# DECODER0_MSVDX_VEC register map
Vendor: Texas Instruments
Peripheral module from a debugger description file (folder J7ES).
Registers are 32-bit, read-write, reset 0x0 unless marked. A register's access mark holds for its fields unless they carry their own. Offsets are as the file gives them; lines under a group give offsets from that group; [hi:lo] are bit positions; {n}, {i} and the like mark numbered series; 'fields as' and 'values as' point back to an identical list; <NAME> marks a mode.

## DECODER0_MSVDX_VEC
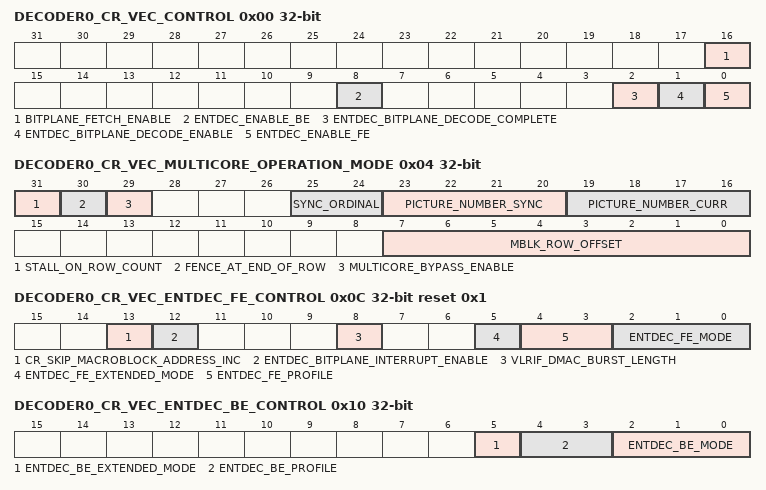
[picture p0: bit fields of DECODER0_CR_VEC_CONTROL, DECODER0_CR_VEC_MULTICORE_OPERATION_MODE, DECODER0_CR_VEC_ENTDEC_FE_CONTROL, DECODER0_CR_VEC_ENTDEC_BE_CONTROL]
0x00 DECODER0_CR_VEC_CONTROL
  [16] BITPLANE_FETCH_ENABLE — Setting this bit will cause the h/w to fetch the bit plane data from the address specified at VEC_VC1_FE_BITPLANES_BASE_ADDR0 [0x418].
  [8] ENTDEC_ENABLE_BE — Setting this bit to '1' instructs the back-end EntDec parser to start parsing the Rendec stream.
  [2] ENTDEC_BITPLANE_DECODE_COMPLETE — This is a status bit to indicate if parsing of the Bit Plane data has completed or not.
  [1] ENTDEC_BITPLANE_DECODE_ENABLE — Setting this bit to '1' instructs the VC-1 Bit Plane decoder to start parsing the stream.
  [0] ENTDEC_ENABLE_FE — Setting this bit to '1' instructs the front-end EntDec parser to start parsing the bit stream.
0x04 DECODER0_CR_VEC_MULTICORE_OPERATION_MODE
  [31] STALL_ON_ROW_COUNT — Enable the multicore support
  [30] FENCE_AT_END_OF_ROW — Insert a fence operation into the memory interface for the last write of the macroblock row before updating the macroblock row count
  [29] MULTICORE_BYPASS_ENABLE — Instead of providing the vdeb macroblock_row_count from the current core, bypass the vdeb macroblock_row_count from the upper core to the lower core in the chain
  [25:24] SYNC_ORDINAL — Sync core ordinal allows the dependent upstream core [and associated sync value] to be selected.
  [23:20] PICTURE_NUMBER_SYNC — Picture number value to be compared to the sync value passed from the upstream decode core.
  [19:16] PICTURE_NUMBER_CURR — Picture number value of the current decode to be passed to the downstream decode core.
  [7:0] MBLK_ROW_OFFSET — Macroblock row offset to be subtracted from the external macroblock row count.
0x08 DECODER0_CR_VEC_COPRO_TARGET — Controls the target module that is accessed by the MTX co-pro port.
  [2:0] COPRO_TARGET
0x0C DECODER0_CR_VEC_ENTDEC_FE_CONTROL reset 0x1
  [13] CR_SKIP_MACROBLOCK_ADDRESS_INC — Indicates that the SW has already extracted the macroblock_inc value and placed it in cr_macroblock_address_inc.
  [12] ENTDEC_BITPLANE_INTERRUPT_ENABLE — When this bit is set to '1', the completion of VC-1 Bit Plane decoding is notified via VEC_END_OF_SLICE bit of interrupt status register of MSVDX.
  [8] VLRIF_DMAC_BURST_LENGTH — DMAC-CH1 burst length control set up by VLRIF when fetching the bitplane data or slice group map data from memory.
  [5] ENTDEC_FE_EXTENDED_MODE — Provides an extension to the ENTDEC_FE_MODE field to allow additional codecs.
  [4:3] ENTDEC_FE_PROFILE — Defines profile for the front-end of Entdec [definition based on ENTDEC_FE_MODE]
  [2:0] ENTDEC_FE_MODE — Define which standard the stream [being processed by the front-end] belongs to
0x10 DECODER0_CR_VEC_ENTDEC_BE_CONTROL
  [5] ENTDEC_BE_EXTENDED_MODE — Provies an extension to the ENTDEC_BE_MODE field
  [4:3] ENTDEC_BE_PROFILE — Defines profile for the back-end of Entdec [definition based on ENTDEC_BE_MODE]
  [2:0] ENTDEC_BE_MODE — Define which standard the stream [being processed by the back-end] belongs to
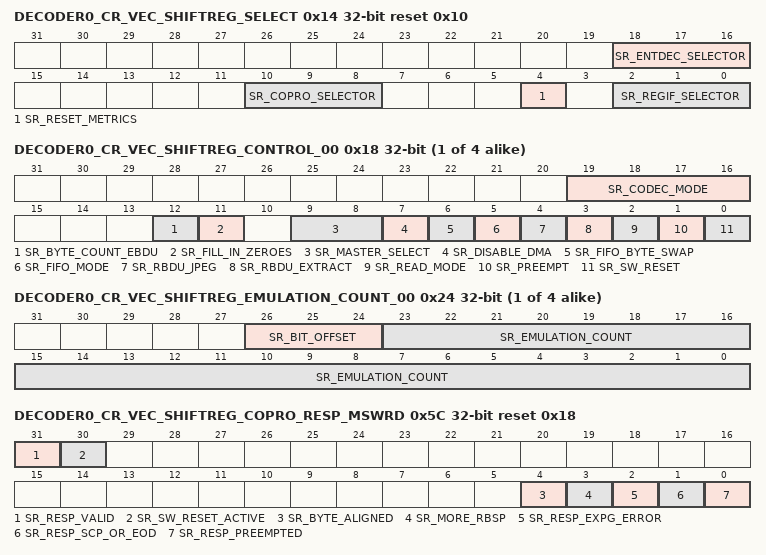
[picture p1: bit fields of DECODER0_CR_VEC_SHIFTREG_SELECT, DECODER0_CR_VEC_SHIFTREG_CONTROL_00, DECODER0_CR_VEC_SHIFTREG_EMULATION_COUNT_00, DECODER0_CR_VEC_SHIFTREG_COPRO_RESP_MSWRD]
0x14 DECODER0_CR_VEC_SHIFTREG_SELECT reset 0x10
  [18:16] SR_ENTDEC_SELECTOR — Used to select the instance of the Shift Register that can be accessed by the Entropy Decoder
  [10:8] SR_COPRO_SELECTOR — Used to select the instance of the Shift Register that can be accessed via the MTX Co-processor Port
  [4] SR_RESET_METRICS — Reset all the metric values in all instances of the Shift Register
  [2:0] SR_REGIF_SELECTOR — Used to select the instance of the Shift Register that can be accessed via the register interface
{0x18+0x10*i} DECODER0_CR_VEC_SHIFTREG_CONTROL_{i:02} (i=0..3)
  [19:16] SR_CODEC_MODE — Codec mode which the shift register works in [affects emulation prevention detection and other operations fro JPEG].
  [12] SR_BYTE_COUNT_EBDU — If SR_RBDU_EXTRACT is set, then this field affects how byte count works
  [11] SR_FILL_IN_ZEROES — If SR_READ_MODE = 0 and byte count is set, then fifo will be filled in zeroes when byte count becomes zero
  [9:8] SR_MASTER_SELECT — Specifies which requestor is the master of this Shift Register channel
  [7] SR_DISABLE_DMA — Controls the assertion of DREQ from ShiftReg to DMAC
  [6] SR_FIFO_BYTE_SWAP — Controls whether the
  [5] SR_FIFO_MODE — Controls whether ShiftReg FIFO is used as a
  [4] SR_RBDU_JPEG — When set, indicates that the RBDU should be based on JPEG stuffed bytes rather than the emualtion bytes of other standards
  [3] SR_RBDU_EXTRACT — Controls 'raw bit stream data unit' extraction
  [2] SR_READ_MODE — Controls whether Start Code Prefixes are detected or whether byte_count is used to control the amount of data read through the ShiftReg
  [1] SR_PREEMPT — Allows pre-emption of any pending MTX ShiftReg Co-processor read
  [0] SR_SW_RESET — Shift Register software reset
{0x1C+0x10*i} DECODER0_CR_VEC_SHIFTREG_BYTE_COUNT_{i:02} reset 0xFFFFFF (i=0..3) — Used to control the amount of bit stream data that can be read through the Shift RegisterNOTE: Writing to this register clears the End-of-Data flag and allows more bit stream data to be read through the Shift Register
  [31:0] SR_BYTE_COUNT — Count of bytes that should be processed before returning control to MTX.
{0x20+0x10*i} DECODER0_CR_VEC_SHIFTREG_STREAMIN_{i:02} (i=0..3)
  [7:0] SR_STREAMIN — Input for the compressed bit stream
{0x24+0x10*i} DECODER0_CR_VEC_SHIFTREG_EMULATION_COUNT_{i:02} ro (i=0..3)
  [26:24] SR_BIT_OFFSET — In byte count mode, SR_BYTE_COUNT*8 + SR_BIT_OFFSET indicates the number of bits left [this is mainly for firmware to know the bit offset at the end of a slice header].
  [23:0] SR_EMULATION_COUNT — If SR_RBDU_EXTRACT is set, this field indicates the number of emulation prevention bytes which have been removed [where the count is aligned to the actual bits consumed from the shift register]
0x5C DECODER0_CR_VEC_SHIFTREG_COPRO_RESP_MSWRD reset 0x18 — Provides direct access to the most significant 32-bits of the Shift Register co-processor response port
  [31] SR_RESP_VALID — Indicates the Shift Register response contains valid data.
  [30] SR_SW_RESET_ACTIVE — Indicates whether the Shift Register is being reset
  [4] SR_BYTE_ALIGNED — Indicates whether the next bit in the Shift Register is byte aligned
  [3] SR_MORE_RBSP — Use to signal more raw bit stream data
  [2] SR_RESP_EXPG_ERROR
  [1] SR_RESP_SCP_OR_EOD
  [0] SR_RESP_PREEMPTED
0x60 DECODER0_CR_VEC_SHIFTREG_COPRO_RESP_LSWRD — Provides direct access to the least significant 32-bits of the Shift Register co-processor response port
  [31:0] SR_RESP_VALUE — Requested bits or signed/unsigned Exp-Goulomb value
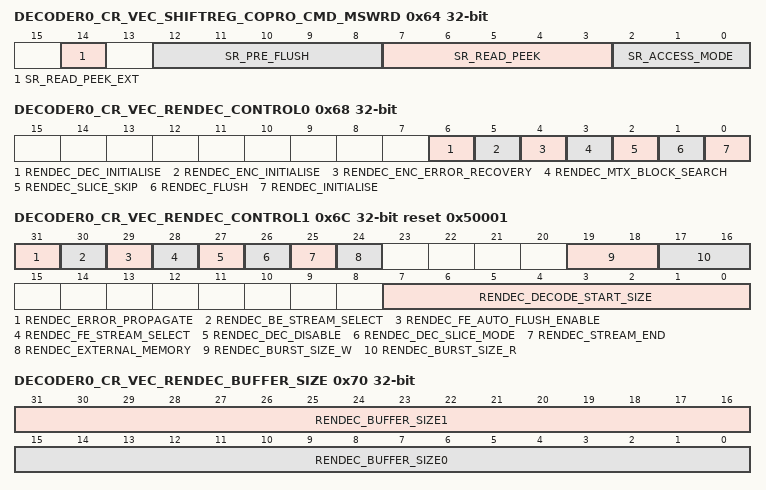
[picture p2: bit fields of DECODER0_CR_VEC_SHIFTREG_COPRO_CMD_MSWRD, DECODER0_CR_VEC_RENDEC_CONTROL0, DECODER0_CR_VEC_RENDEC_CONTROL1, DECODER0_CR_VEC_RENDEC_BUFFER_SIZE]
0x64 DECODER0_CR_VEC_SHIFTREG_COPRO_CMD_MSWRD — Provides direct access to the most significant 32-bits of the Shift Register co-processor command port
  [14] SR_READ_PEEK_EXT — Read Peek Extended.
  [12:8] SR_PRE_FLUSH — Discard or flush bits from the bit stream before read/peek/skip - 0 to 31
  [7:3] SR_READ_PEEK — The number of bits to read/peek - 0 to
  [2:0] SR_ACCESS_MODE — The access mode:
0x68 DECODER0_CR_VEC_RENDEC_CONTROL0
  [6] RENDEC_DEC_INITIALISE — Writing 1 to this bit initialises the Rendec decoder contexts to the default value.
  [5] RENDEC_ENC_INITIALISE — Writing 1 to this bit initialises the Rendec encoder contexts to the default value.
  [4] RENDEC_ENC_ERROR_RECOVERY — When a lock-up is detected at the front-end, s/w must write 1 to this bit before resetting the front-end modules.
  [3] RENDEC_MTX_BLOCK_SEARCH — Writing '1' to this bit instructs the back-end of entdec to search for the MTX_to_MTX header.
  [2] RENDEC_SLICE_SKIP — Writing '1' to this bit instructs the Rendec/decoder to skip to the next slice.
  [1] RENDEC_FLUSH — Writing '1' to this bit flushes the Rendec/encoder remaining bit stream with [if necessary] some extra bits so that the encoded bit stream is aligned to the programmed memory burst size.
  [0] RENDEC_INITIALISE — Writing 1 to this bit initialises the Rendec encoder/decoder contexts to the default value.
0x6C DECODER0_CR_VEC_RENDEC_CONTROL1 reset 0x50001
  [31] RENDEC_ERROR_PROPAGATE — Error flag control for rendec.
  [30] RENDEC_BE_STREAM_SELECT — Rendec stream select for back-end.
  [29] RENDEC_FE_AUTO_FLUSH_ENABLE — Rendec is flushed upon the front-end parser and vec_fe_end_of_slice interrupt is set when the rendec flush is completed
  [28] RENDEC_FE_STREAM_SELECT — Rendec stream select for front-end.
  [27] RENDEC_DEC_DISABLE — Rendec Decoder Disable mode.
  [26] RENDEC_DEC_SLICE_MODE — Rendec Decoder operates in slice mode
  [25] RENDEC_STREAM_END — The s/w must set this bit when the front-end parser has completed the decoding of the stream.
  [24] RENDEC_EXTERNAL_MEMORY — Used to enable/disable the use of external memory:
  [19:18] RENDEC_BURST_SIZE_W — Burst size of the Rendec write in memory-words [1 word = 16 bytes]
  [17:16] RENDEC_BURST_SIZE_R — Burst size of the Rendec read in memory-words [1 word = 16 bytes]
  [7:0] RENDEC_DECODE_START_SIZE — The Rendec decode start control, specified in
0x70 DECODER0_CR_VEC_RENDEC_BUFFER_SIZE
  [31:16] RENDEC_BUFFER_SIZE1 — The size of the Rendec buffer 1 in external memory in units of 4kB.
  [15:0] RENDEC_BUFFER_SIZE0 — The size of the Rendec buffer 0 in external memory in 4kB.
0x74 DECODER0_CR_VEC_RENDEC_BASE_ADDR0
  [31:12] RENDEC_BASE_ADDR0 — Base address 0 of the Rendec external memory buffer, the buffer must be aligned to a 4kB boundary
0x78 DECODER0_CR_VEC_RENDEC_BASE_ADDR1
  [31:12] RENDEC_BASE_ADDR1 — Base address 1 of the Rendec external memory buffer, the buffer must be aligned to a 4kB boundary
0x7C DECODER0_CR_VEC_RENDEC_WRITE_ADDR0
  [27:4] RENDEC_WRITE_ADDR0 — Write address pointer 0.
0x80 DECODER0_CR_VEC_RENDEC_WRITE_ADDR1
  [27:4] RENDEC_WRITE_ADDR1 — Write address pointer 1.
0x84 DECODER0_CR_VEC_RENDEC_READ_ADDR0
  [27:4] RENDEC_READ_ADDR0 — External buffer read address
0x88 DECODER0_CR_VEC_RENDEC_READ_ADDR1
  [27:4] RENDEC_READ_ADDR1 — External buffer read address
0x8C DECODER0_CR_VEC_RENDEC_DATA_SIZE0 ro
  [27:0] RENDEC_DATA_SIZE0 — The size of the Rendec stream data 0 currently stored in the external memory buffer [in bytes]
0x90 DECODER0_CR_VEC_RENDEC_DATA_SIZE1 ro
  [27:0] RENDEC_DATA_SIZE1 — The size of the Rendec stream data 1 currently stored in the external memory buffer [in bytes]
0x94 DECODER0_CR_VEC_RENDEC_WRITE_DATA
  [31:0] RENDEC_WRITE_DATA — The value to be written to Rendec for MTX/Host messages
0x98 DECODER0_CR_VEC_RENDEC_READ_DATA
  [31:0] RENDEC_READ_DATA — The value provided from Rendec to extract MTX/Host messages
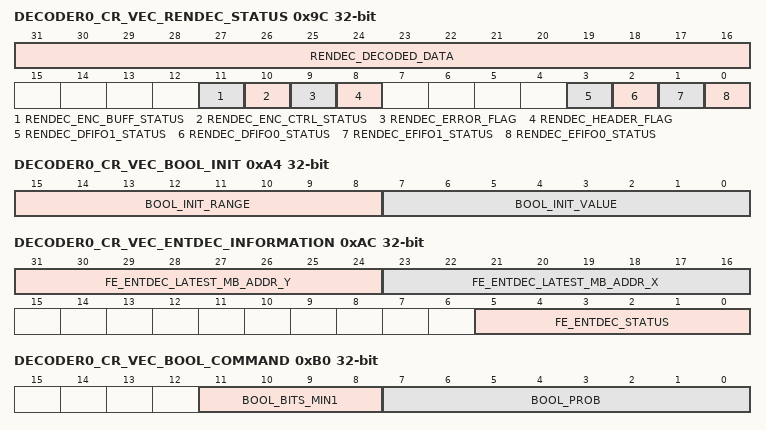
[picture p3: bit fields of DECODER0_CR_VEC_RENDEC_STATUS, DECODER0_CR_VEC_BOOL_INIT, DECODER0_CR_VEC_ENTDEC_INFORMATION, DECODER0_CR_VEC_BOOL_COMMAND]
0x9C DECODER0_CR_VEC_RENDEC_STATUS ro
  [31:16] RENDEC_DECODED_DATA — This is a real-time monitor of the currently decoded Rendec data.
  [11] RENDEC_ENC_BUFF_STATUS
  [10] RENDEC_ENC_CTRL_STATUS
  [9] RENDEC_ERROR_FLAG — This bit is set when the currently decoded Rendec data contains an error
  [8] RENDEC_HEADER_FLAG — Indicates whether the currently decoded Rendec data is the header after EndOfSlice or not.
  [3] RENDEC_DFIFO1_STATUS — Empty_flag status of the Rendec decoder FIFO1
  [2] RENDEC_DFIFO0_STATUS — Empty_flag status of the Rendec decoder FIFO0
  [1] RENDEC_EFIFO1_STATUS — Full_flag status of the Rendec encoder FIFO1
  [0] RENDEC_EFIFO0_STATUS — Full_flag status of the Rendec encoder FIFO0
0xA0 DECODER0_CR_VEC_RENDEC_SLICE_COUNT
  [19:0] RENDEC_SLICE_COUNT — Rendec Differential Slice Counter for the primary rendec stream.
0xA4 DECODER0_CR_VEC_BOOL_INIT — Initialises the context of the Bool-Coder internal state.
  [15:8] BOOL_INIT_RANGE — The initial range for the Bool-Coder.
  [7:0] BOOL_INIT_VALUE — The initial value of the Bool-Coder.
0xA8 DECODER0_CR_VEC_BOOL_CTRL — Controls the master access to the Bool-Coder.
  [1:0] BOOL_MASTER_SELECT — Selects the master controller for the Bool-Coder.
0xAC DECODER0_CR_VEC_ENTDEC_INFORMATION ro
  [31:24] FE_ENTDEC_LATEST_MB_ADDR_Y — Provides the latest macroblock vertical address that has been successfully decoded by Entdec
  [23:16] FE_ENTDEC_LATEST_MB_ADDR_X — Provides the latest macroblock horizontal address that has been successfully decoded by Entdec
  [5:0] FE_ENTDEC_STATUS — Indicates the real-time status of Entdec front-end parser.
0xB0 DECODER0_CR_VEC_BOOL_COMMAND — A write to this register triggers a Bool decode operation. It also causes the Bool-Coder Result Register to be cleared to 0.
  [11:8] BOOL_BITS_MIN1 — Indicates the number of Bools - 1 that should be decoded.
  [7:0] BOOL_PROB — The probability to be used for all Bools to be decoded.
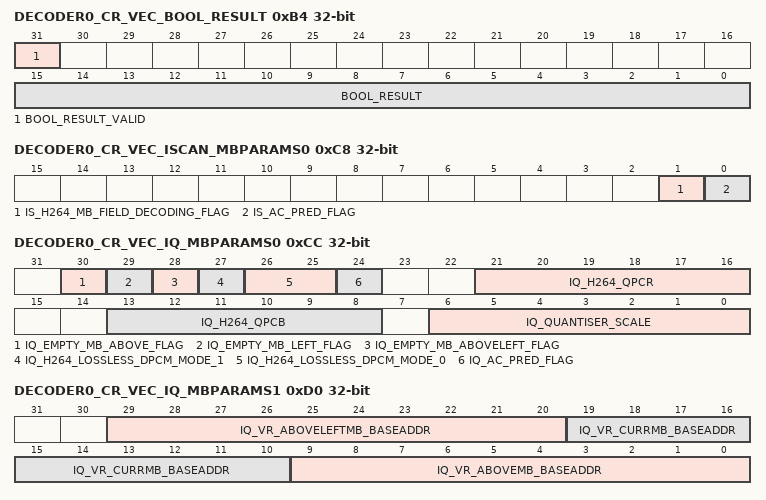
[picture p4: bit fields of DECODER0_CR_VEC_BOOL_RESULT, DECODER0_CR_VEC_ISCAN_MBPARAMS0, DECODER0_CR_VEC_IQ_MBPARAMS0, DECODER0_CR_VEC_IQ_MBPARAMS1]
0xB4 DECODER0_CR_VEC_BOOL_RESULT ro — Register contains the result of a bool-decode operation. It is cleared to 0, when a write to the Bool-Coder Command Register occurs, and updated with the result when it has been calculated.
  [31] BOOL_RESULT_VALID — Indicates that the BOOL_RESULT field contains the result from the previously executed command.
  [15:0] BOOL_RESULT — The result from the previously executed command, with Bools left-shifted into the result field in the order they are decoded.
0xB8 DECODER0_CR_VEC_DIRECT_MODE_CONTROL
  [2:0] DIRECT_MODE — Direct mode setting.
0xBC DECODER0_CR_VEC_DIRECT_MODE_DATA0
  [31:0] DIRECT_DATA0 — Direct mode data register 0.
0xC0 DECODER0_CR_VEC_COMMAND_SIGNATURE
  [31:0] COMMAND_SIGNATURE — Signature data for the commands [address &amp; data].
0xC4 DECODER0_CR_VEC_IXFORM_SIGNATURE
  [31:0] IXFORM_SIGNATURE — Signature data for the output of iXform module.
0xC8 DECODER0_CR_VEC_ISCAN_MBPARAMS0
  [1] IS_H264_MB_FIELD_DECODING_FLAG — H.264 mb_field_decoding_flag
  [0] IS_AC_PRED_FLAG — AC_PRED_FLAG used in MPEG4 / VC-1 / WMV9
0xCC DECODER0_CR_VEC_IQ_MBPARAMS0
  [30] IQ_EMPTY_MB_ABOVE_FLAG — Empty flag for the top macroblock
  [29] IQ_EMPTY_MB_LEFT_FLAG — Empty flag for the left macroblock
  [28] IQ_EMPTY_MB_ABOVELEFT_FLAG — Empty flag for the left macroblock
  [27] IQ_H264_LOSSLESS_DPCM_MODE_1 — Bit 0 of Luma Block 1 DPCM mode for H264 Lossless codec.
  [26:25] IQ_H264_LOSSLESS_DPCM_MODE_0 — Luma Block 0 DPCM mode for H264 Lossless codec.
  [24] IQ_AC_PRED_FLAG — AC_PRED_FLAG for iQ
  [21:16] IQ_H264_QPCR — QPCr value in H.264
  [13:8] IQ_H264_QPCB — QPCb value in H.264
  [6:0] IQ_QUANTISER_SCALE — The quantisation parameters shared between different standards
0xD0 DECODER0_CR_VEC_IQ_MBPARAMS1
  [29:20] IQ_VR_ABOVELEFTMB_BASEADDR — Base address of the above-left macroblock in VEC Local RAM
  [19:10] IQ_VR_CURRMB_BASEADDR — Base address of the current macroblock in VEC Local RAM
  [9:0] IQ_VR_ABOVEMB_BASEADDR — Base address of the above macroblock in VEC Local RAM
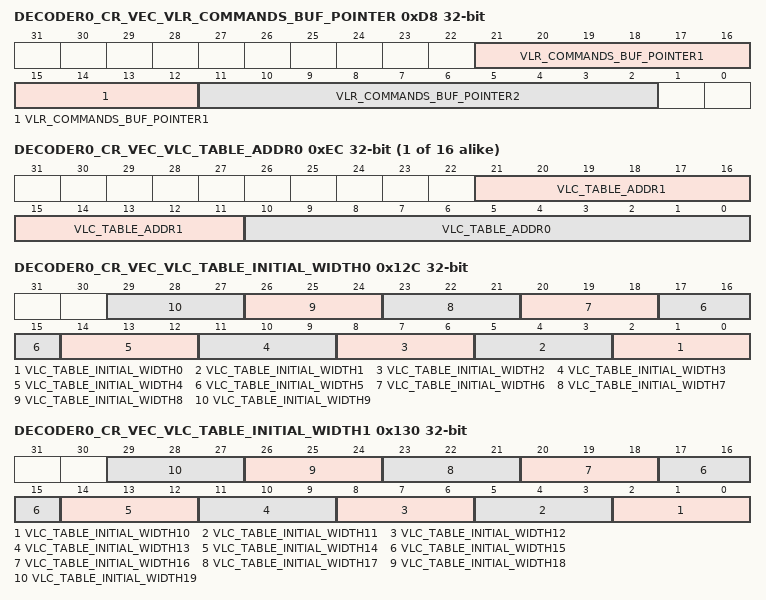
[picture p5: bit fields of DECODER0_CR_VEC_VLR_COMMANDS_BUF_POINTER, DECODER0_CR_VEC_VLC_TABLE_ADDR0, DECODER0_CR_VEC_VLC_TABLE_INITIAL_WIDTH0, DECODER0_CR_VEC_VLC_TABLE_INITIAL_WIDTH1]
0xD8 DECODER0_CR_VEC_VLR_COMMANDS_BUF_POINTER ro — Register set by hardware and read by software. It indicates the address of the first command of the macroblock cmd sequence of the second macroblock before current
  [21:12] VLR_COMMANDS_BUF_POINTER1 — Field set by hardware and read by software.
  [11:2] VLR_COMMANDS_BUF_POINTER2 — Field set by hardware and read by software.
0xDC DECODER0_CR_VEC_CIRC_BUFF_BASE_ADDR
  [11:2] CIRC_BUFF_BASE_ADDR — Base address in the VEC Local RAM of the circular buffers
0xE0 DECODER0_CR_VEC_SGM_BITPLANE_BASE_ADDR — Base address within VEC Local RAM for Slice Group Map / Bit-Plane Data that are fetched from main memory into this circulate buffer
  [11:2] SGM_BITPLANE_BASE_ADDR — Base address in VEC Local RAM of:
0xE4 DECODER0_CR_VEC_VLR_COMMANDS_STORE — Register defining the base address of commands to store into VEC local ram. Storing of commands is requied for slice switching
  [11:2] VLR_COMMANDS_STORE_BASE_ADDRESS — The commands for the latest 2 macroblocks generated by ENTDEC are stored into the VEC Local RAM at the address specified by this register, if the processing stream at the back-end is either H.264 or AVS
0xE8 DECODER0_CR_VEC_VLR_COMMANDS_NUM
  [6:0] VLR_COMMANDS_STORE_NUMBER_OF_CMDS — Field defining the actual number of commands stored in the VEC local ram Range
{0xEC+4i} DECODER0_CR_VEC_VLC_TABLE_ADDR{i} (i=0..15)
  [21:11] VLC_TABLE_ADDR{2i+1} — Base address of VLC Table {2i+1}
  [10:0] VLC_TABLE_ADDR{2i} — Base address of VLC Table {2i}
0x12C DECODER0_CR_VEC_VLC_TABLE_INITIAL_WIDTH0
  [3n+2:3n] VLC_TABLE_INITIAL_WIDTH{n} (n=0..9) — Initial width of VLC Table {n}
0x130 DECODER0_CR_VEC_VLC_TABLE_INITIAL_WIDTH1
  [3n-28:3n-30] VLC_TABLE_INITIAL_WIDTH{n} (n=10..19) — Initial width of VLC Table {n}
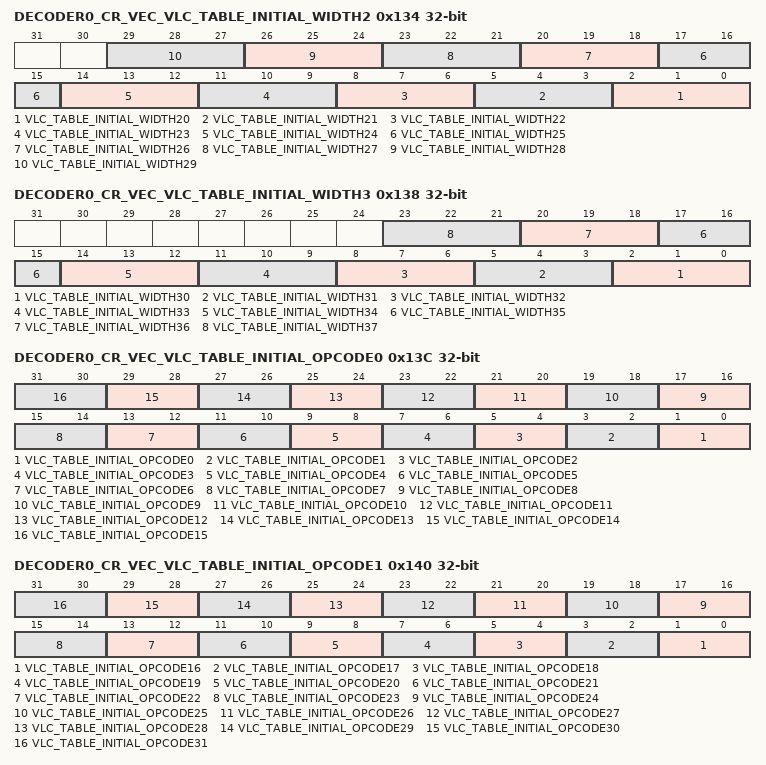
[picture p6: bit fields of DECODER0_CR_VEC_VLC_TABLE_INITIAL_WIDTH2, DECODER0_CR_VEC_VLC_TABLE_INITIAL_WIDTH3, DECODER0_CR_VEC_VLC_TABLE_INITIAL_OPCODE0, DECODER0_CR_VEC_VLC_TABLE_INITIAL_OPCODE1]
0x134 DECODER0_CR_VEC_VLC_TABLE_INITIAL_WIDTH2
  [3n-58:3n-60] VLC_TABLE_INITIAL_WIDTH{n} (n=20..29) — Initial width of VLC Table {n}
0x138 DECODER0_CR_VEC_VLC_TABLE_INITIAL_WIDTH3
  [3n-88:3n-90] VLC_TABLE_INITIAL_WIDTH{n} (n=30..37) — Initial width of VLC Table {n}
0x13C DECODER0_CR_VEC_VLC_TABLE_INITIAL_OPCODE0
  [2n+1:2n] VLC_TABLE_INITIAL_OPCODE{n} (n=0..15) — Initial opcode of VLC Table {n}
0x140 DECODER0_CR_VEC_VLC_TABLE_INITIAL_OPCODE1
  [2n-31:2n-32] VLC_TABLE_INITIAL_OPCODE{n} (n=16..31) — Initial opcode of VLC Table {n}
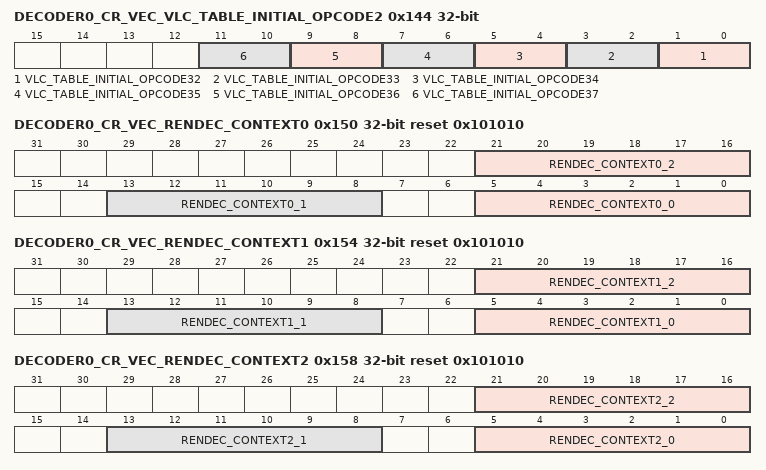
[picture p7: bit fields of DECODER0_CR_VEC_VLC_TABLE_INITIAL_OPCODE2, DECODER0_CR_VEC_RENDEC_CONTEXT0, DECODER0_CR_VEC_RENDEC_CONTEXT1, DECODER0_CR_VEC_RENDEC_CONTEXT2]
0x144 DECODER0_CR_VEC_VLC_TABLE_INITIAL_OPCODE2
  [2n-63:2n-64] VLC_TABLE_INITIAL_OPCODE{n} (n=32..37) — Initial opcode of VLC Table {n}
0x150 DECODER0_CR_VEC_RENDEC_CONTEXT0 reset 0x101010
  [21:16] RENDEC_CONTEXT0_2 — Rendec initial context value for signed data
  [13:8] RENDEC_CONTEXT0_1 — Rendec initial context value for signed data
  [5:0] RENDEC_CONTEXT0_0 — Rendec initial context value for signed data
0x154 DECODER0_CR_VEC_RENDEC_CONTEXT1 reset 0x101010
  [21:16] RENDEC_CONTEXT1_2 — Rendec initial context value for unsigned data
  [13:8] RENDEC_CONTEXT1_1 — Rendec initial context value for unsigned data
  [5:0] RENDEC_CONTEXT1_0 — Rendec initial context value for unsigned data
0x158 DECODER0_CR_VEC_RENDEC_CONTEXT2 reset 0x101010
  [21:16] RENDEC_CONTEXT2_2 — Rendec initial context value for significance map data
  [13:8] RENDEC_CONTEXT2_1 — Rendec initial context value for significance map data
  [5:0] RENDEC_CONTEXT2_0 — Rendec initial context value for significance map data
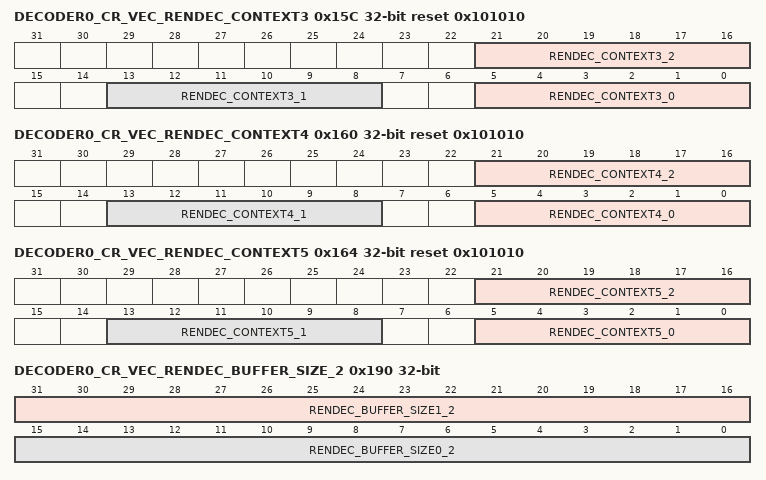
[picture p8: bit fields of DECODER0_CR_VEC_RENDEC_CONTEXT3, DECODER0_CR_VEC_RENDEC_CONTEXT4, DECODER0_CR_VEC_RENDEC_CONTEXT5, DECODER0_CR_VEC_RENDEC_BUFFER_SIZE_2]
0x15C DECODER0_CR_VEC_RENDEC_CONTEXT3 reset 0x101010
  [21:16] RENDEC_CONTEXT3_2 — Rendec initial context value for residual coefficients
  [13:8] RENDEC_CONTEXT3_1 — Rendec initial context value for residual coefficients
  [5:0] RENDEC_CONTEXT3_0 — Rendec initial context value for residual coefficients
0x160 DECODER0_CR_VEC_RENDEC_CONTEXT4 reset 0x101010
  [21:16] RENDEC_CONTEXT4_2 — Rendec initial context value for NumSymbolsLess1
  [13:8] RENDEC_CONTEXT4_1 — Rendec initial context value for NumSymbolsLess1
  [5:0] RENDEC_CONTEXT4_0 — Rendec initial context value for NumSymbolsLess1
0x164 DECODER0_CR_VEC_RENDEC_CONTEXT5 reset 0x101010
  [21:16] RENDEC_CONTEXT5_2 — Rendec initial context value for header data
  [13:8] RENDEC_CONTEXT5_1 — Rendec initial context value for header data
  [5:0] RENDEC_CONTEXT5_0 — Rendec initial context value for header data
0x168 DECODER0_CR_STREAM_ID
  [7:0] STREAM_ID — stream id set up by host or mtx, of which value is reflected onto the output port of MSVDX.
0x16C DECODER0_CR_STREAM_COUNTER
  [31:0] STREAM_COUNTER — counter set up by host or mtx, of which value is reflected onto the output port of MSVDX.
0x170 DECODER0_CR_SR_ACTIVE_CYCLES ro
  [25:0] SR_ACTIVE_CYCLES — Records the number of cycles when the hardware is parsing the bitstream
0x174 DECODER0_CR_SR_INACTIVE_CYCLES ro
  [25:0] SR_INACTIVE_CYCLES — Records the number of cycles that the parsers are inactive
0x178 DECODER0_CR_SR_BITS_CONSUMED ro
  [25:0] SR_BITS_CONSUMED — Records the number of bits that have been consumed from the bitstream
0x17C DECODER0_CR_VEC_CONTROL_2
  [1:0] SR_BURST_SIZE — Specifies the DMA burst size in number of memory words for shift-reg.
0x180 DECODER0_CR_VEC_BE_ENTDEC_SYNC
  [0] BE_ENTDEC_SYNC_FLAG — Used for the back-end h/w parser's synchronisation
0x188 DECODER0_CR_VEC_RENDEC_INPUT_SIGNATURE
  [31:0] RENDEC_INPUT_SIGNATURE — The signature value captured upon every end of slice at the input of the rendec encoder
0x18C DECODER0_CR_VEC_RENDEC_OUTPUT_SIGNATURE
  [31:0] RENDEC_OUTPUT_SIGNATURE — The signature value captured upon every end of slice at the output of the rendec decoder
0x190 DECODER0_CR_VEC_RENDEC_BUFFER_SIZE_2
  [31:16] RENDEC_BUFFER_SIZE1_2 — The size of the Rendec buffer 1 in external memory in units of 4kB for secondary rendec port.
  [15:0] RENDEC_BUFFER_SIZE0_2 — The size of the Rendec buffer 0 in external memory in 4kB for secondary rendec port.
0x194 DECODER0_CR_VEC_RENDEC_BASE_ADDR0_2
  [31:12] RENDEC_BASE_ADDR0_2 — Base address 0 of the Rendec external memory buffer for secondary rendec port, the buffer must be aligned to a 4kB boundary
0x198 DECODER0_CR_VEC_RENDEC_BASE_ADDR1_2
  [31:12] RENDEC_BASE_ADDR1_2 — Base address 1 of the Rendec external memory buffer for secondary rendec port, the buffer must be aligned to a 4kB boundary
0x19C DECODER0_CR_VEC_RENDEC_WRITE_ADDR0_2
  [27:4] RENDEC_WRITE_ADDR0_2 — Write address pointer 0 for secondary rendec port.
0x1A0 DECODER0_CR_VEC_RENDEC_WRITE_ADDR1_2
  [27:4] RENDEC_WRITE_ADDR1_2 — Write address pointer 1 for secondary rendec port.
0x1A4 DECODER0_CR_VEC_RENDEC_READ_ADDR0_2
  [27:4] RENDEC_READ_ADDR0_2 — External buffer read address 0 for secondary rendec port - can only be updated when the MTX has control of the read part of the Rendec
0x1A8 DECODER0_CR_VEC_RENDEC_READ_ADDR1_2
  [27:4] RENDEC_READ_ADDR1_2 — External buffer read address 1 for secondary rendec port - can only be updated when the MTX has control of the read part of the Rendec
0x1AC DECODER0_CR_VEC_RENDEC_DATA_SIZE0_2 ro
  [27:0] RENDEC_DATA_SIZE0_2 — The size of the Rendec stream data 0 currently stored in the external memory buffer for secondary rendec port [in bytes]
0x1B0 DECODER0_CR_VEC_RENDEC_DATA_SIZE1_2 ro
  [27:0] RENDEC_DATA_SIZE1_2 — The size of the Rendec stream data 1 currently stored in the external memory buffer for secondary rendec port [in bytes]
0x1B4 DECODER0_CR_VEC_RENDEC_SLICE_COUNT_2
  [19:0] RENDEC_SLICE_COUNT_2 — Rendec Differential Slice Counter for the secondary rendec stream.
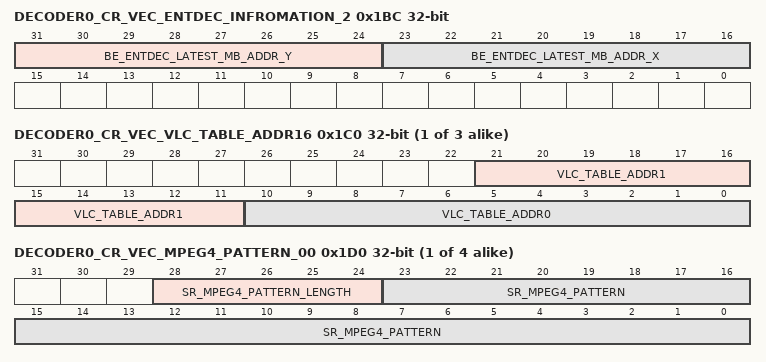
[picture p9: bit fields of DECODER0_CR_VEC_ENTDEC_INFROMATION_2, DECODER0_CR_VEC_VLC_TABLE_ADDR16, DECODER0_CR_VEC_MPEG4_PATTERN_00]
0x1BC DECODER0_CR_VEC_ENTDEC_INFROMATION_2 ro
  [31:24] BE_ENTDEC_LATEST_MB_ADDR_Y — Latest good decoded mb address y
  [23:16] BE_ENTDEC_LATEST_MB_ADDR_X — Latest good mb address x
{0x180+4i} DECODER0_CR_VEC_VLC_TABLE_ADDR{i} (i=16..18)
  fields as DECODER0_CR_VEC_VLC_TABLE_ADDR0
{0x1D0+4i} DECODER0_CR_VEC_MPEG4_PATTERN_{i:02} (i=0..3) — is used for detecting header patterns in MPEG4
  [28:24] SR_MPEG4_PATTERN_LENGTH — Length of pattern to be matched counting from the msb down.
  [23:0] SR_MPEG4_PATTERN — Pattern to be used for detecting the end of data for MPEG4.
0x1E0 DECODER0_CR_VEC_FRAME_ID
  [31:0] VEC_FRAME_ID — When bit-stream status parameters are output via a hardware interface, the contents of this register are also output to identify the stream and frame the parameters are from [which may be used to align the parameters to the corresponding commands from the back-end]
0x1E4 DECODER0_CR_MSVDX_PARAMS_SIGNATURE — MSVDX Bitstream Params Signature from the Parsers (For H264 and MPEG2)
  [31:0] MSVDX_PARAMS_SIGNATURE — Signature data for the params count interface from the H264 and MPEG2 parsers.
{0x360+4i} DECODER0_CR_SR_CRC_{i:02} (i=0..7) — Contains the CRC signature for write data into the shift register FIFO
  [31:0] SR_SIGNATURE — Signature CRC for shift register input data to FIFO
